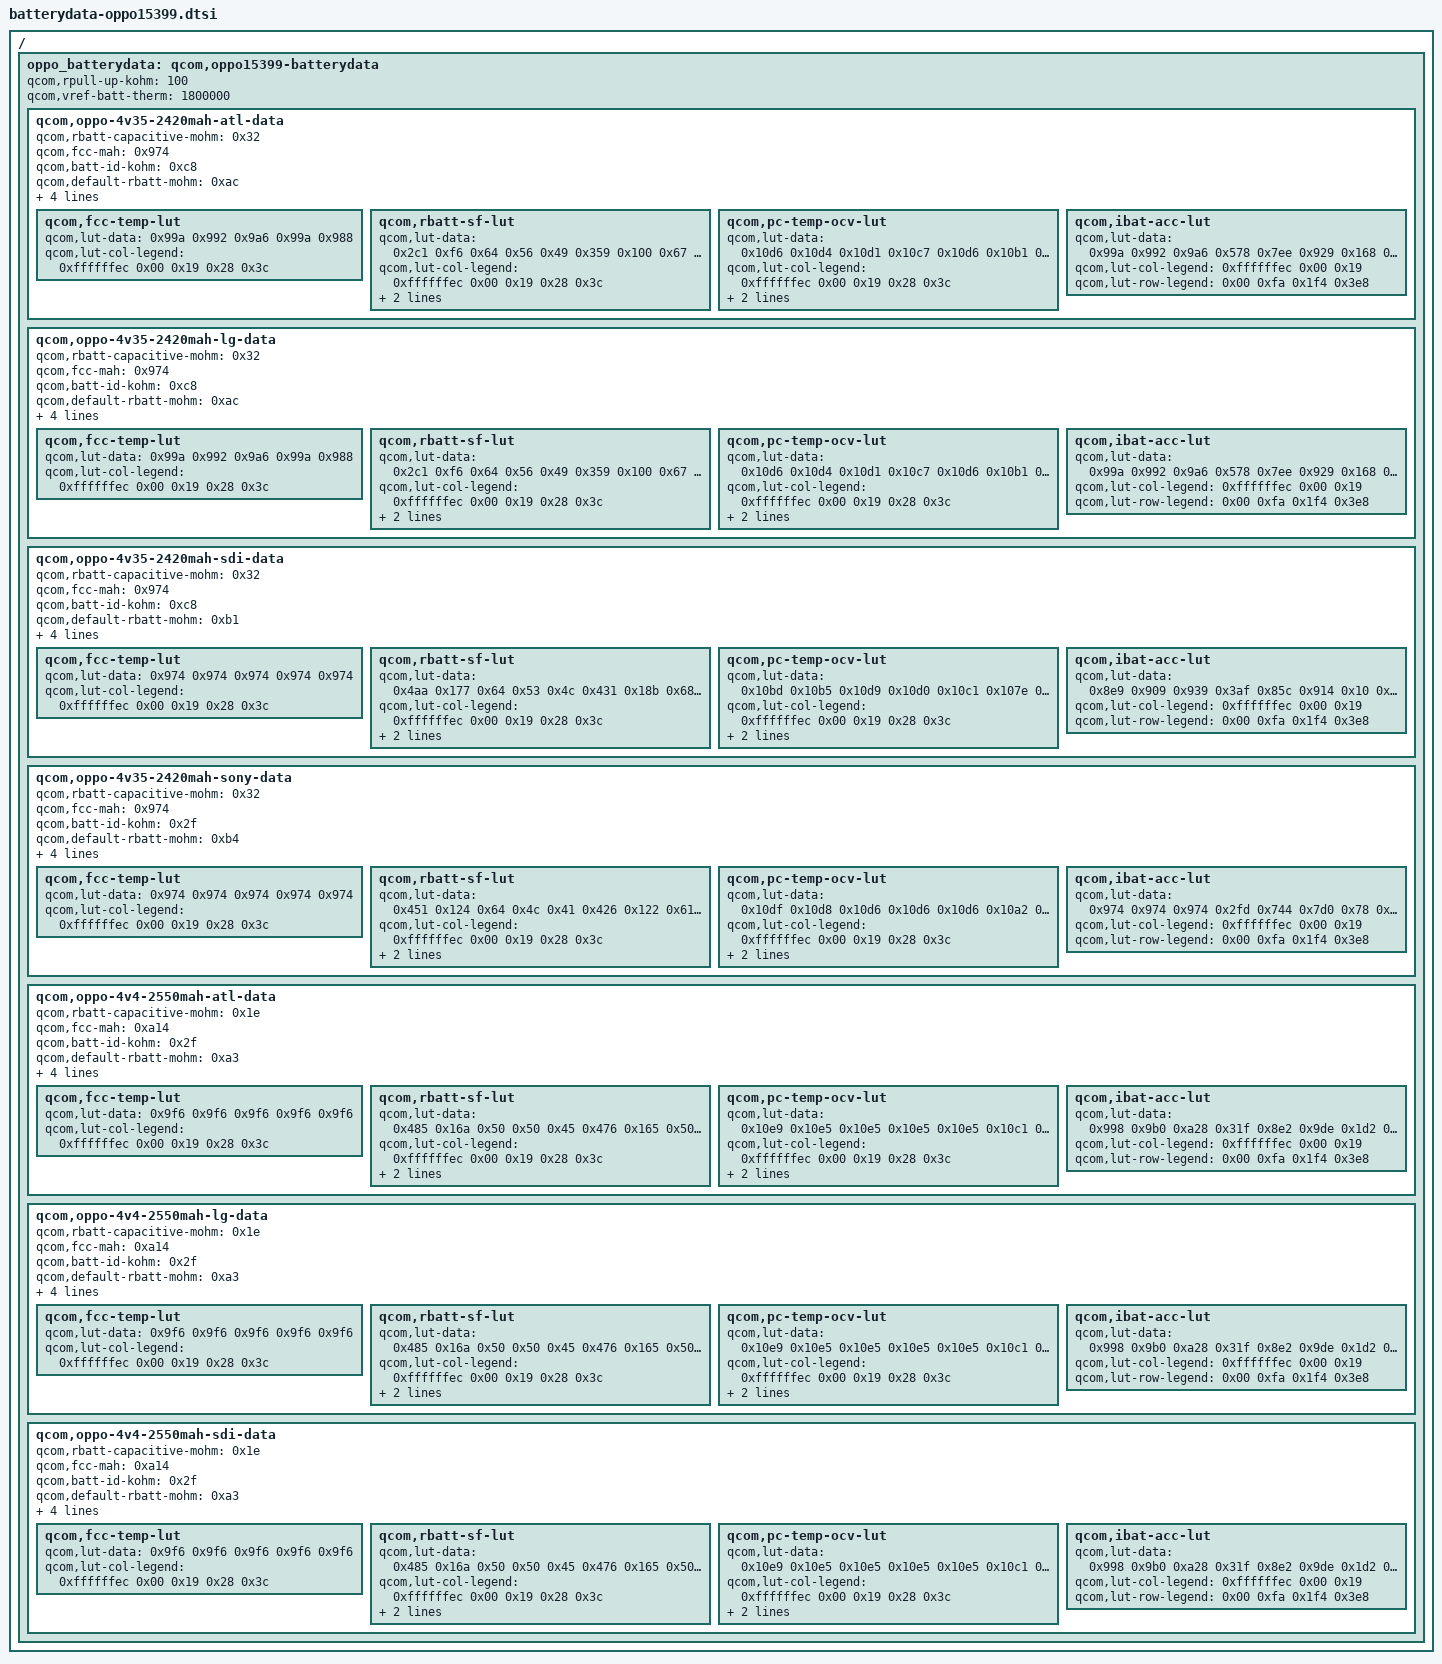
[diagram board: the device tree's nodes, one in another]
/* OPPO A37f (15399) fuel-gauge battery profiles — ported verbatim from the
 * live device-tree dump (~/a37f-dumps/live-refs/live-dt/qcom,battery-data-*).
 * Each live vendor container held one profile; here all 7 are collected into a
 * single qpnp-vm-bms container (referenced by &pm8916_bms). Profile node names
 * were made unique (per vendor); every value/LUT is unchanged ground truth.
 *
 * NOTE: live batt-id-kohm is shared (atl/lg/sdi=200; sony/high-*=47), so the
 * per-vendor and 4v35-vs-4v4 selection is an OPPO-custom mechanism the generic
 * vm-bms lacks — it first-matches by batt-id. Faithful data; selection caveat.
 */

/ {
	oppo_batterydata: qcom,oppo15399-batterydata {
		qcom,rpull-up-kohm = <100>;
		qcom,vref-batt-therm = <1800000>;

		qcom,oppo-4v35-2420mah-atl-data {
			qcom,rbatt-capacitive-mohm = <0x32>;
			qcom,fcc-mah = <0x974>;
			qcom,batt-id-kohm = <0xc8>;
			qcom,default-rbatt-mohm = <0xac>;
			qcom,flat-ocv-threshold-uv = <0x39fbc0>;
			qcom,v-cutoff-uv = <0x33e140>;
			qcom,battery-type = "oppo_4v35_2420mah_atl";
			qcom,max-voltage-uv = <0x426030>;
			qcom,fcc-temp-lut {
			qcom,lut-data = <0x99a 0x992 0x9a6 0x99a 0x988>;
			qcom,lut-col-legend = <0xffffffec 0x00 0x19 0x28 0x3c>;
			};
			qcom,rbatt-sf-lut {
			qcom,lut-data = <0x2c1 0xf6 0x64 0x56 0x49 0x359 0x100 0x67 0x56 0x4e 0x388 0x104 0x6b 0x58 0x4c 0x376 0x109 0x6c 0x5b 0x4e 0x33f 0x10d 0x70 0x5d 0x4f 0x350 0x115 0x75 0x5f 0x50 0x36d 0x111 0x76 0x63 0x54 0x30d 0x111 0x7c 0x69 0x56 0x32a 0x100 0x75 0x67 0x5a 0x339 0xfa 0x65 0x59 0x50 0x30c 0xf9 0x60 0x56 0x4e 0x317 0x100 0x63 0x58 0x4e 0x343 0x104 0x62 0x5a 0x4f 0x360 0x126 0x63 0x5b 0x52 0x371 0x103 0x64 0x58 0x4d 0x3c5 0x10b 0x62 0x54 0x4d 0x450 0x114 0x62 0x55 0x4d 0x43f 0x11c 0x61 0x56 0x4d 0x4a2 0x124 0x61 0x57 0x4d 0x4d1 0x12c 0x63 0x57 0x4f 0x518 0x13a 0x64 0x59 0x50 0x541 0x140 0x68 0x5d 0x52 0x569 0x153 0x6c 0x5e 0x52 0x598 0x172 0x6f 0x5d 0x52 0x60f 0x185 0x73 0x61 0x52 0x65c 0x19c 0x73 0x60 0x53 0xfd1 0x1c7 0x76 0x63 0x57 0x1d83 0x1ef 0x7d 0x65 0x5b 0x2f84 0x224 0x81 0x74 0x69 0x5ea2 0x27c 0x91 0x92 0x81 0x21053 0x1e80c 0x12c 0x125 0x12c>;
			qcom,lut-col-legend = <0xffffffec 0x00 0x19 0x28 0x3c>;
			qcom,lut-row-legend = <0x64 0x5f 0x5a 0x55 0x50 0x4b 0x46 0x41 0x3c 0x37 0x32 0x2d 0x28 0x23 0x1e 0x19 0x14 0x10 0x0d 0x0b 0x0a 0x09 0x08 0x07 0x06 0x05 0x04 0x03 0x02 0x01 0x00>;
			};
			qcom,pc-temp-ocv-lut {
			qcom,lut-data = <0x10d6 0x10d4 0x10d1 0x10c7 0x10d6 0x10b1 0x10bf 0x10ae 0x109e 0x10a6 0x1074 0x1085 0x107c 0x1067 0x106d 0x103a 0x104f 0x104a 0x1032 0x1036 0x1002 0x101b 0x1018 0xffe 0x1004 0xfc6 0xfe4 0xfe6 0xfc5 0xfca 0xf84 0xfac 0xfc3 0xf99 0xf9f 0xf59 0xf7b 0xfa3 0xf72 0xf76 0xf35 0xf4b 0xf7b 0xf48 0xf4e 0xf14 0xf22 0xf4d 0xf17 0xf1e 0xef9 0xf05 0xf1a 0xefa 0xf01 0xee0 0xef0 0xefe 0xee0 0xeea 0xecc 0xedf 0xee9 0xece 0xed7 0xebf 0xecf 0xed7 0xec0 0xec7 0xeb6 0xec3 0xec8 0xeb0 0xeb2 0xea9 0xeba 0xebb 0xe9e 0xe94 0xe98 0xeaa 0xead 0xe8b 0xe80 0xe85 0xe90 0xe97 0xe73 0xe67 0xe78 0xe78 0xe7e 0xe5c 0xe55 0xe6f 0xe73 0xe6c 0xe56 0xe51 0xe68 0xe71 0xe64 0xe55 0xe50 0xe5b 0xe6d 0xe62 0xe52 0xe4e 0xe52 0xe68 0xe5f 0xe4e 0xe4c 0xe37 0xe62 0xe56 0xe3f 0xe3e 0xe21 0xe59 0xe46 0xe24 0xe28 0xdfe 0xe1c 0xdfd 0xdfe 0xe06 0xdce 0xded 0xdc9 0xdce 0xddd 0xd91 0xdb0 0xd83 0xd91 0xda7 0xd40 0xd5e 0xd24 0xd40 0xd01 0xcc8 0xce1 0xc81 0xcc8 0xca8 0xbb8 0xbb8 0xbb8 0xbb8 0xbb8>;
			qcom,lut-col-legend = <0xffffffec 0x00 0x19 0x28 0x3c>;
			qcom,lut-row-legend = <0x64 0x5f 0x5a 0x55 0x50 0x4b 0x46 0x41 0x3c 0x37 0x32 0x2d 0x28 0x23 0x1e 0x19 0x14 0x10 0x0d 0x0b 0x0a 0x09 0x08 0x07 0x06 0x05 0x04 0x03 0x02 0x01 0x00>;
			};
			qcom,ibat-acc-lut {
			qcom,lut-data = <0x99a 0x992 0x9a6 0x578 0x7ee 0x929 0x168 0x690 0x906 0x00 0x3fc 0x898>;
			qcom,lut-col-legend = <0xffffffec 0x00 0x19>;
			qcom,lut-row-legend = <0x00 0xfa 0x1f4 0x3e8>;
			};
		};

		qcom,oppo-4v35-2420mah-lg-data {
			qcom,rbatt-capacitive-mohm = <0x32>;
			qcom,fcc-mah = <0x974>;
			qcom,batt-id-kohm = <0xc8>;
			qcom,default-rbatt-mohm = <0xac>;
			qcom,flat-ocv-threshold-uv = <0x39fbc0>;
			qcom,v-cutoff-uv = <0x33e140>;
			qcom,battery-type = "oppo_4v35_2420mah_lg";
			qcom,max-voltage-uv = <0x426030>;
			qcom,fcc-temp-lut {
			qcom,lut-data = <0x99a 0x992 0x9a6 0x99a 0x988>;
			qcom,lut-col-legend = <0xffffffec 0x00 0x19 0x28 0x3c>;
			};
			qcom,rbatt-sf-lut {
			qcom,lut-data = <0x2c1 0xf6 0x64 0x56 0x49 0x359 0x100 0x67 0x56 0x4e 0x388 0x104 0x6b 0x58 0x4c 0x376 0x109 0x6c 0x5b 0x4e 0x33f 0x10d 0x70 0x5d 0x4f 0x350 0x115 0x75 0x5f 0x50 0x36d 0x111 0x76 0x63 0x54 0x30d 0x111 0x7c 0x69 0x56 0x32a 0x100 0x75 0x67 0x5a 0x339 0xfa 0x65 0x59 0x50 0x30c 0xf9 0x60 0x56 0x4e 0x317 0x100 0x63 0x58 0x4e 0x343 0x104 0x62 0x5a 0x4f 0x360 0x126 0x63 0x5b 0x52 0x371 0x103 0x64 0x58 0x4d 0x3c5 0x10b 0x62 0x54 0x4d 0x450 0x114 0x62 0x55 0x4d 0x43f 0x11c 0x61 0x56 0x4d 0x4a2 0x124 0x61 0x57 0x4d 0x4d1 0x12c 0x63 0x57 0x4f 0x518 0x13a 0x64 0x59 0x50 0x541 0x140 0x68 0x5d 0x52 0x569 0x153 0x6c 0x5e 0x52 0x598 0x172 0x6f 0x5d 0x52 0x60f 0x185 0x73 0x61 0x52 0x65c 0x19c 0x73 0x60 0x53 0xfd1 0x1c7 0x76 0x63 0x57 0x1d83 0x1ef 0x7d 0x65 0x5b 0x2f84 0x224 0x81 0x74 0x69 0x5ea2 0x27c 0x91 0x92 0x81 0x21053 0x1e80c 0x12c 0x125 0x12c>;
			qcom,lut-col-legend = <0xffffffec 0x00 0x19 0x28 0x3c>;
			qcom,lut-row-legend = <0x64 0x5f 0x5a 0x55 0x50 0x4b 0x46 0x41 0x3c 0x37 0x32 0x2d 0x28 0x23 0x1e 0x19 0x14 0x10 0x0d 0x0b 0x0a 0x09 0x08 0x07 0x06 0x05 0x04 0x03 0x02 0x01 0x00>;
			};
			qcom,pc-temp-ocv-lut {
			qcom,lut-data = <0x10d6 0x10d4 0x10d1 0x10c7 0x10d6 0x10b1 0x10bf 0x10ae 0x109e 0x10a6 0x1074 0x1085 0x107c 0x1067 0x106d 0x103a 0x104f 0x104a 0x1032 0x1036 0x1002 0x101b 0x1018 0xffe 0x1004 0xfc6 0xfe4 0xfe6 0xfc5 0xfca 0xf84 0xfac 0xfc3 0xf99 0xf9f 0xf59 0xf7b 0xfa3 0xf72 0xf76 0xf35 0xf4b 0xf7b 0xf48 0xf4e 0xf14 0xf22 0xf4d 0xf17 0xf1e 0xef9 0xf05 0xf1a 0xefa 0xf01 0xee0 0xef0 0xefe 0xee0 0xeea 0xecc 0xedf 0xee9 0xece 0xed7 0xebf 0xecf 0xed7 0xec0 0xec7 0xeb6 0xec3 0xec8 0xeb0 0xeb2 0xea9 0xeba 0xebb 0xe9e 0xe94 0xe98 0xeaa 0xead 0xe8b 0xe80 0xe85 0xe90 0xe97 0xe73 0xe67 0xe78 0xe78 0xe7e 0xe5c 0xe55 0xe6f 0xe73 0xe6c 0xe56 0xe51 0xe68 0xe71 0xe64 0xe55 0xe50 0xe5b 0xe6d 0xe62 0xe52 0xe4e 0xe52 0xe68 0xe5f 0xe4e 0xe4c 0xe37 0xe62 0xe56 0xe3f 0xe3e 0xe21 0xe59 0xe46 0xe24 0xe28 0xdfe 0xe1c 0xdfd 0xdfe 0xe06 0xdce 0xded 0xdc9 0xdce 0xddd 0xd91 0xdb0 0xd83 0xd91 0xda7 0xd40 0xd5e 0xd24 0xd40 0xd01 0xcc8 0xce1 0xc81 0xcc8 0xca8 0xbb8 0xbb8 0xbb8 0xbb8 0xbb8>;
			qcom,lut-col-legend = <0xffffffec 0x00 0x19 0x28 0x3c>;
			qcom,lut-row-legend = <0x64 0x5f 0x5a 0x55 0x50 0x4b 0x46 0x41 0x3c 0x37 0x32 0x2d 0x28 0x23 0x1e 0x19 0x14 0x10 0x0d 0x0b 0x0a 0x09 0x08 0x07 0x06 0x05 0x04 0x03 0x02 0x01 0x00>;
			};
			qcom,ibat-acc-lut {
			qcom,lut-data = <0x99a 0x992 0x9a6 0x578 0x7ee 0x929 0x168 0x690 0x906 0x00 0x3fc 0x898>;
			qcom,lut-col-legend = <0xffffffec 0x00 0x19>;
			qcom,lut-row-legend = <0x00 0xfa 0x1f4 0x3e8>;
			};
		};

		qcom,oppo-4v35-2420mah-sdi-data {
			qcom,rbatt-capacitive-mohm = <0x32>;
			qcom,fcc-mah = <0x974>;
			qcom,batt-id-kohm = <0xc8>;
			qcom,default-rbatt-mohm = <0xb1>;
			qcom,flat-ocv-threshold-uv = <0x39fbc0>;
			qcom,v-cutoff-uv = <0x33e140>;
			qcom,battery-type = "oppo_4v35_2420mah_sdi";
			qcom,max-voltage-uv = <0x426030>;
			qcom,fcc-temp-lut {
			qcom,lut-data = <0x974 0x974 0x974 0x974 0x974>;
			qcom,lut-col-legend = <0xffffffec 0x00 0x19 0x28 0x3c>;
			};
			qcom,rbatt-sf-lut {
			qcom,lut-data = <0x4aa 0x177 0x64 0x53 0x4c 0x431 0x18b 0x68 0x56 0x4e 0x3df 0x172 0x6a 0x53 0x4c 0x3ac 0x172 0x6c 0x55 0x50 0x38d 0x15c 0x65 0x57 0x50 0x355 0x155 0x6e 0x5e 0x52 0x346 0x14d 0x6b 0x5c 0x59 0x346 0x139 0x73 0x63 0x5c 0x344 0x125 0x6a 0x52 0x4f 0x346 0x124 0x62 0x4e 0x4c 0x34f 0x139 0x63 0x55 0x50 0x363 0x124 0x60 0x53 0x50 0x373 0x123 0x60 0x59 0x52 0x38b 0x136 0x63 0x5a 0x53 0x3b0 0x14d 0x62 0x56 0x52 0x3de 0x155 0x63 0x53 0x4f 0x416 0x162 0x66 0x57 0x4f 0x439 0x180 0x69 0x53 0x50 0x46f 0x18f 0x6c 0x55 0x50 0x48b 0x1a1 0x65 0x57 0x53 0x4a2 0x1b2 0x63 0x56 0x50 0x4b4 0x1b7 0x64 0x59 0x50 0x4dd 0x1d4 0x65 0x59 0x56 0x4f4 0x1cc 0x69 0x5c 0x53 0x511 0x1ee 0x6b 0x59 0x52 0x526 0x1e2 0x6c 0x59 0x55 0x541 0x1f0 0x6f 0x59 0x57 0x55b 0x1f6 0x72 0x5c 0x5a 0x59b 0x218 0x77 0x74 0x6e 0x69d 0x261 0xb6 0x2c4 0x1d0 0x7b7 0x333 0x14b 0x338 0x226>;
			qcom,lut-col-legend = <0xffffffec 0x00 0x19 0x28 0x3c>;
			qcom,lut-row-legend = <0x64 0x5f 0x5a 0x55 0x50 0x4b 0x46 0x41 0x3c 0x37 0x32 0x2d 0x28 0x23 0x1e 0x19 0x14 0x10 0x0d 0x0b 0x0a 0x09 0x08 0x07 0x06 0x05 0x04 0x03 0x02 0x01 0x00>;
			};
			qcom,pc-temp-ocv-lut {
			qcom,lut-data = <0x10bd 0x10b5 0x10d9 0x10d0 0x10c1 0x107e 0x107d 0x109e 0x1097 0x1089 0x1049 0x1047 0x1068 0x105f 0x1051 0x101c 0x101e 0x1035 0x102d 0x101e 0xfec 0xff1 0x1000 0xff7 0xff4 0xfa6 0xfbb 0xfd9 0xfd5 0xfc5 0xf63 0xf7c 0xf98 0xfa0 0xf99 0xf45 0xf61 0xf80 0xf7d 0xf73 0xf2d 0xf36 0xf4d 0xf43 0xf3f 0xf13 0xf0f 0xf1c 0xf1e 0xf16 0xefa 0xef5 0xf01 0xf01 0xf01 0xee5 0xee2 0xeeb 0xef1 0xeeb 0xed4 0xed3 0xed9 0xee1 0xedc 0xecb 0xec7 0xecc 0xed0 0xecc 0xec1 0xeb9 0xebd 0xeba 0xeaf 0xeb5 0xeb1 0xeac 0xea6 0xe9a 0xea3 0xe9f 0xe9a 0xe98 0xe83 0xe93 0xe8b 0xe82 0xe7c 0xe6e 0xe87 0xe72 0xe6f 0xe6a 0xe5c 0xe82 0xe6e 0xe67 0xe69 0xe5c 0xe7f 0xe6c 0xe66 0xe67 0xe59 0xe7d 0xe6c 0xe65 0xe67 0xe58 0xe76 0xe6a 0xe64 0xe62 0xe54 0xe71 0xe68 0xe63 0xe5d 0xe4d 0xe69 0xe66 0xe56 0xe4a 0xe37 0xe5b 0xe57 0xe3b 0xe24 0xe15 0xe47 0xe39 0xe14 0xdf8 0xdea 0xe2c 0xe12 0xde1 0xdc0 0xdb2 0xdd2 0xd9e 0xda0 0xd06 0xd01 0xd34 0xd38 0xca1 0xc47 0xc4f 0xbb8 0xbb8 0xbb8 0xbb8 0xbb8>;
			qcom,lut-col-legend = <0xffffffec 0x00 0x19 0x28 0x3c>;
			qcom,lut-row-legend = <0x64 0x5f 0x5a 0x55 0x50 0x4b 0x46 0x41 0x3c 0x37 0x32 0x2d 0x28 0x23 0x1e 0x19 0x14 0x10 0x0d 0x0b 0x0a 0x09 0x08 0x07 0x06 0x05 0x04 0x03 0x02 0x01 0x00>;
			};
			qcom,ibat-acc-lut {
			qcom,lut-data = <0x8e9 0x909 0x939 0x3af 0x85c 0x914 0x10 0x577 0x8f4 0x00 0x566 0x8a9>;
			qcom,lut-col-legend = <0xffffffec 0x00 0x19>;
			qcom,lut-row-legend = <0x00 0xfa 0x1f4 0x3e8>;
			};
		};

		qcom,oppo-4v35-2420mah-sony-data {
			qcom,rbatt-capacitive-mohm = <0x32>;
			qcom,fcc-mah = <0x974>;
			qcom,batt-id-kohm = <0x2f>;
			qcom,default-rbatt-mohm = <0xb4>;
			qcom,flat-ocv-threshold-uv = <0x39fbc0>;
			qcom,v-cutoff-uv = <0x33e140>;
			qcom,battery-type = "oppo_4v35_2420mah_sony";
			qcom,max-voltage-uv = <0x426030>;
			qcom,fcc-temp-lut {
			qcom,lut-data = <0x974 0x974 0x974 0x974 0x974>;
			qcom,lut-col-legend = <0xffffffec 0x00 0x19 0x28 0x3c>;
			};
			qcom,rbatt-sf-lut {
			qcom,lut-data = <0x451 0x124 0x64 0x4c 0x41 0x426 0x122 0x61 0x4c 0x42 0x3f2 0x119 0x61 0x4c 0x41 0x3cd 0x117 0x64 0x4c 0x43 0x3bc 0x114 0x66 0x51 0x45 0x3b8 0x11d 0x67 0x4f 0x43 0x3b0 0x116 0x6c 0x53 0x46 0x3ac 0x119 0x70 0x56 0x48 0x3a9 0x119 0x72 0x55 0x4b 0x3aa 0x10f 0x6b 0x51 0x46 0x3b3 0x108 0x66 0x4c 0x42 0x3be 0x112 0x67 0x4c 0x44 0x3ca 0x119 0x67 0x4f 0x48 0x3e9 0x11a 0x66 0x53 0x49 0x40c 0x12c 0x6b 0x51 0x45 0x43d 0x13a 0x6a 0x4e 0x44 0x47d 0x146 0x6a 0x4e 0x44 0x4c6 0x156 0x6b 0x4c 0x44 0x50a 0x16c 0x6d 0x4e 0x44 0x567 0x181 0x6f 0x52 0x46 0x58d 0x191 0x73 0x55 0x47 0x5bd 0x1a3 0x7a 0x53 0x49 0x5f2 0x1b6 0x7f 0x58 0x4a 0x630 0x1c8 0x83 0x58 0x4c 0x640 0x1e3 0x84 0x56 0x4b 0x6a4 0x203 0x87 0x56 0x4b 0x708 0x235 0x8e 0x58 0x4e 0x76c 0x274 0x99 0x63 0x53 0x7d0 0x2e2 0xab 0x65 0x5a 0x1388 0x3e8 0xe8 0x7e 0x6a 0x21053 0x1e80c 0xe6cf 0x144 0xd0>;
			qcom,lut-col-legend = <0xffffffec 0x00 0x19 0x28 0x3c>;
			qcom,lut-row-legend = <0x64 0x5f 0x5a 0x55 0x50 0x4b 0x46 0x41 0x3c 0x37 0x32 0x2d 0x28 0x23 0x1e 0x19 0x14 0x10 0x0d 0x0b 0x0a 0x09 0x08 0x07 0x06 0x05 0x04 0x03 0x02 0x01 0x00>;
			};
			qcom,pc-temp-ocv-lut {
			qcom,lut-data = <0x10df 0x10d8 0x10d6 0x10d6 0x10d6 0x10a2 0x109c 0x10a1 0x10a4 0x109a 0x1065 0x106a 0x106d 0x1072 0x105d 0x102f 0x103f 0x1042 0x1045 0x1032 0xffd 0x100b 0x100f 0x1013 0x1000 0xfcc 0xfd6 0xfe0 0xfd8 0xfd0 0xf94 0xfa2 0xfab 0xfac 0xf9b 0xf6d 0xf7e 0xf85 0xf86 0xf75 0xf3e 0xf57 0xf5f 0xf5f 0xf4f 0xf1a 0xf28 0xf33 0xf34 0xf22 0xefe 0xf05 0xf0d 0xf0d 0xf00 0xee9 0xef0 0xef0 0xef4 0xee9 0xed9 0xede 0xede 0xee2 0xed7 0xece 0xed0 0xecf 0xed3 0xec7 0xec5 0xec9 0xec3 0xec5 0xeb1 0xeba 0xebe 0xeaf 0xeaf 0xe8f 0xea5 0xea2 0xe9a 0xe95 0xe7a 0xe8d 0xe82 0xe7e 0xe78 0xe5f 0xe7a 0xe74 0xe68 0xe64 0xe4d 0xe6d 0xe6d 0xe64 0xe63 0xe4a 0xe68 0xe6c 0xe63 0xe61 0xe47 0xe60 0xe69 0xe5e 0xe5b 0xe45 0xe56 0xe61 0xe59 0xe57 0xe40 0xe46 0xe54 0xe4e 0xe4d 0xe36 0xe36 0xe36 0xe33 0xe37 0xe1d 0xe0e 0xe07 0xe07 0xe0e 0xdf7 0xddb 0xdca 0xdd0 0xddd 0xdc8 0xd98 0xd77 0xd87 0xd9d 0xd8b 0xd41 0xcfe 0xd24 0xd44 0xd3e 0xcc0 0xc86 0xc86 0xcc6 0xcce 0xbb8 0xbb8 0xbb8 0xbb8 0xbb8>;
			qcom,lut-col-legend = <0xffffffec 0x00 0x19 0x28 0x3c>;
			qcom,lut-row-legend = <0x64 0x5f 0x5a 0x55 0x50 0x4b 0x46 0x41 0x3c 0x37 0x32 0x2d 0x28 0x23 0x1e 0x19 0x14 0x10 0x0d 0x0b 0x0a 0x09 0x08 0x07 0x06 0x05 0x04 0x03 0x02 0x01 0x00>;
			};
			qcom,ibat-acc-lut {
			qcom,lut-data = <0x974 0x974 0x974 0x2fd 0x744 0x7d0 0x78 0x668 0x7c6 0x00 0x4ce 0x778>;
			qcom,lut-col-legend = <0xffffffec 0x00 0x19>;
			qcom,lut-row-legend = <0x00 0xfa 0x1f4 0x3e8>;
			};
		};

		qcom,oppo-4v4-2550mah-atl-data {
			qcom,rbatt-capacitive-mohm = <0x1e>;
			qcom,fcc-mah = <0xa14>;
			qcom,batt-id-kohm = <0x2f>;
			qcom,default-rbatt-mohm = <0xa3>;
			qcom,flat-ocv-threshold-uv = <0x3abf10>;
			qcom,v-cutoff-uv = <0x33e140>;
			qcom,battery-type = "oppo_4400_2550mah_ATL";
			qcom,max-voltage-uv = <0x432380>;
			qcom,fcc-temp-lut {
			qcom,lut-data = <0x9f6 0x9f6 0x9f6 0x9f6 0x9f6>;
			qcom,lut-col-legend = <0xffffffec 0x00 0x19 0x28 0x3c>;
			};
			qcom,rbatt-sf-lut {
			qcom,lut-data = <0x485 0x16a 0x50 0x50 0x45 0x476 0x165 0x50 0x53 0x49 0x452 0x15e 0x66 0x54 0x4c 0x42e 0x156 0x69 0x5a 0x4b 0x408 0x153 0x6a 0x59 0x4e 0x3f3 0x159 0x6f 0x59 0x50 0x3c9 0x144 0x71 0x5f 0x4e 0x3bc 0x144 0x77 0x63 0x50 0x3b6 0x127 0x70 0x5f 0x53 0x3af 0x12b 0x61 0x56 0x4c 0x3b7 0x12a 0x5f 0x50 0x49 0x3c3 0x130 0x61 0x51 0x49 0x3c6 0x131 0x64 0x53 0x4b 0x3da 0x137 0x67 0x57 0x51 0x402 0x139 0x61 0x53 0x49 0x42b 0x13b 0x60 0x4e 0x49 0x467 0x13e 0x64 0x53 0x4b 0x4b5 0x140 0x64 0x56 0x4b 0x4f8 0x169 0x62 0x54 0x49 0x520 0x174 0x63 0x53 0x4e 0x532 0x17d 0x65 0x57 0x4c 0x560 0x17f 0x68 0x56 0x4b 0x579 0x185 0x6c 0x57 0x4e 0x594 0x189 0x71 0x5c 0x4c 0x5b0 0x197 0x6e 0x59 0x4e 0x5f9 0x1a5 0x6d 0x59 0x4b 0x61e 0x1af 0x72 0x5a 0x4e 0x64d 0x1c0 0x7a 0x60 0x53 0x687 0x1f3 0x81 0x68 0x5a 0x673 0x227 0x326 0xaa 0x6b 0x11eb 0x325 0x395 0xe5 0x2f2>;
			qcom,lut-col-legend = <0xffffffec 0x00 0x19 0x28 0x3c>;
			qcom,lut-row-legend = <0x64 0x5f 0x5a 0x55 0x50 0x4b 0x46 0x41 0x3c 0x37 0x32 0x2d 0x28 0x23 0x1e 0x19 0x14 0x10 0x0d 0x0b 0x0a 0x09 0x08 0x07 0x06 0x05 0x04 0x03 0x02 0x01 0x00>;
			};
			qcom,pc-temp-ocv-lut {
			qcom,lut-data = <0x10e9 0x10e5 0x10e5 0x10e5 0x10e5 0x10c1 0x10c5 0x10c5 0x10c5 0x10c5 0x1087 0x107f 0x109b 0x109c 0x1092 0x1052 0x104b 0x1065 0x1068 0x105e 0x1015 0x1017 0x102a 0x102b 0x1029 0xfe7 0xfe4 0xff0 0xff9 0xfee 0xf9e 0xfa6 0xfc1 0xfc2 0xfbf 0xf6d 0xf7b 0xf8e 0xf93 0xf8f 0xf46 0xf4e 0xf65 0xf6c 0xf64 0xf22 0xf22 0xf2c 0xf30 0xf31 0xf06 0xf07 0xf10 0xf14 0xf0f 0xef0 0xeed 0xef5 0xef9 0xef8 0xedd 0xede 0xee5 0xee5 0xee1 0xed0 0xece 0xed4 0xed5 0xed3 0xec7 0xebe 0xec3 0xec5 0xec2 0xebd 0xeaf 0xeb2 0xeaa 0xea0 0xeaf 0xe9d 0xe9f 0xe9b 0xe8d 0xe9f 0xe89 0xe8a 0xe87 0xe79 0xe8f 0xe76 0xe76 0xe73 0xe67 0xe86 0xe74 0xe71 0xe69 0xe5e 0xe81 0xe72 0xe6e 0xe69 0xe5f 0xe7b 0xe71 0xe6d 0xe69 0xe5d 0xe77 0xe70 0xe6e 0xe67 0xe5b 0xe74 0xe6b 0xe69 0xe64 0xe58 0xe71 0xe69 0xe65 0xe61 0xe54 0xe68 0xe5e 0xe56 0xe56 0xe34 0xe62 0xe48 0xe15 0xe1c 0xe14 0xe59 0xe25 0xde8 0xdf4 0xdee 0xe4d 0xdc4 0xdb2 0xdc4 0xdc0 0xe1b 0xd7d 0xcfe 0xd2c 0xd36 0xbb8 0xbb8 0xbb8 0xbb8 0xbb8>;
			qcom,lut-col-legend = <0xffffffec 0x00 0x19 0x28 0x3c>;
			qcom,lut-row-legend = <0x64 0x5f 0x5a 0x55 0x50 0x4b 0x46 0x41 0x3c 0x37 0x32 0x2d 0x28 0x23 0x1e 0x19 0x14 0x10 0x0d 0x0b 0x0a 0x09 0x08 0x07 0x06 0x05 0x04 0x03 0x02 0x01 0x00>;
			};
			qcom,ibat-acc-lut {
			qcom,lut-data = <0x998 0x9b0 0xa28 0x31f 0x8e2 0x9de 0x1d2 0x8da 0x9ca 0x00 0x555 0x970>;
			qcom,lut-col-legend = <0xffffffec 0x00 0x19>;
			qcom,lut-row-legend = <0x00 0xfa 0x1f4 0x3e8>;
			};
		};

		qcom,oppo-4v4-2550mah-lg-data {
			qcom,rbatt-capacitive-mohm = <0x1e>;
			qcom,fcc-mah = <0xa14>;
			qcom,batt-id-kohm = <0x2f>;
			qcom,default-rbatt-mohm = <0xa3>;
			qcom,flat-ocv-threshold-uv = <0x3abf10>;
			qcom,v-cutoff-uv = <0x33e140>;
			qcom,battery-type = "oppo_4400_2550mah_lg";
			qcom,max-voltage-uv = <0x432380>;
			qcom,fcc-temp-lut {
			qcom,lut-data = <0x9f6 0x9f6 0x9f6 0x9f6 0x9f6>;
			qcom,lut-col-legend = <0xffffffec 0x00 0x19 0x28 0x3c>;
			};
			qcom,rbatt-sf-lut {
			qcom,lut-data = <0x485 0x16a 0x50 0x50 0x45 0x476 0x165 0x50 0x53 0x49 0x452 0x15e 0x66 0x54 0x4c 0x42e 0x156 0x69 0x5a 0x4b 0x408 0x153 0x6a 0x59 0x4e 0x3f3 0x159 0x6f 0x59 0x50 0x3c9 0x144 0x71 0x5f 0x4e 0x3bc 0x144 0x77 0x63 0x50 0x3b6 0x127 0x70 0x5f 0x53 0x3af 0x12b 0x61 0x56 0x4c 0x3b7 0x12a 0x5f 0x50 0x49 0x3c3 0x130 0x61 0x51 0x49 0x3c6 0x131 0x64 0x53 0x4b 0x3da 0x137 0x67 0x57 0x51 0x402 0x139 0x61 0x53 0x49 0x42b 0x13b 0x60 0x4e 0x49 0x467 0x13e 0x64 0x53 0x4b 0x4b5 0x140 0x64 0x56 0x4b 0x4f8 0x169 0x62 0x54 0x49 0x520 0x174 0x63 0x53 0x4e 0x532 0x17d 0x65 0x57 0x4c 0x560 0x17f 0x68 0x56 0x4b 0x579 0x185 0x6c 0x57 0x4e 0x594 0x189 0x71 0x5c 0x4c 0x5b0 0x197 0x6e 0x59 0x4e 0x5f9 0x1a5 0x6d 0x59 0x4b 0x61e 0x1af 0x72 0x5a 0x4e 0x64d 0x1c0 0x7a 0x60 0x53 0x687 0x1f3 0x81 0x68 0x5a 0x673 0x227 0x326 0xaa 0x6b 0x11eb 0x325 0x395 0xe5 0x2f2>;
			qcom,lut-col-legend = <0xffffffec 0x00 0x19 0x28 0x3c>;
			qcom,lut-row-legend = <0x64 0x5f 0x5a 0x55 0x50 0x4b 0x46 0x41 0x3c 0x37 0x32 0x2d 0x28 0x23 0x1e 0x19 0x14 0x10 0x0d 0x0b 0x0a 0x09 0x08 0x07 0x06 0x05 0x04 0x03 0x02 0x01 0x00>;
			};
			qcom,pc-temp-ocv-lut {
			qcom,lut-data = <0x10e9 0x10e5 0x10e5 0x10e5 0x10e5 0x10c1 0x10c5 0x10c5 0x10c5 0x10c5 0x1087 0x107f 0x109b 0x109c 0x1092 0x1052 0x104b 0x1065 0x1068 0x105e 0x1015 0x1017 0x102a 0x102b 0x1029 0xfe7 0xfe4 0xff0 0xff9 0xfee 0xf9e 0xfa6 0xfc1 0xfc2 0xfbf 0xf6d 0xf7b 0xf8e 0xf93 0xf8f 0xf46 0xf4e 0xf65 0xf6c 0xf64 0xf22 0xf22 0xf2c 0xf30 0xf31 0xf06 0xf07 0xf10 0xf14 0xf0f 0xef0 0xeed 0xef5 0xef9 0xef8 0xedd 0xede 0xee5 0xee5 0xee1 0xed0 0xece 0xed4 0xed5 0xed3 0xec7 0xebe 0xec3 0xec5 0xec2 0xebd 0xeaf 0xeb2 0xeaa 0xea0 0xeaf 0xe9d 0xe9f 0xe9b 0xe8d 0xe9f 0xe89 0xe8a 0xe87 0xe79 0xe8f 0xe76 0xe76 0xe73 0xe67 0xe86 0xe74 0xe71 0xe69 0xe5e 0xe81 0xe72 0xe6e 0xe69 0xe5f 0xe7b 0xe71 0xe6d 0xe69 0xe5d 0xe77 0xe70 0xe6e 0xe67 0xe5b 0xe74 0xe6b 0xe69 0xe64 0xe58 0xe71 0xe69 0xe65 0xe61 0xe54 0xe68 0xe5e 0xe56 0xe56 0xe34 0xe62 0xe48 0xe15 0xe1c 0xe14 0xe59 0xe25 0xde8 0xdf4 0xdee 0xe4d 0xdc4 0xdb2 0xdc4 0xdc0 0xe1b 0xd7d 0xcfe 0xd2c 0xd36 0xbb8 0xbb8 0xbb8 0xbb8 0xbb8>;
			qcom,lut-col-legend = <0xffffffec 0x00 0x19 0x28 0x3c>;
			qcom,lut-row-legend = <0x64 0x5f 0x5a 0x55 0x50 0x4b 0x46 0x41 0x3c 0x37 0x32 0x2d 0x28 0x23 0x1e 0x19 0x14 0x10 0x0d 0x0b 0x0a 0x09 0x08 0x07 0x06 0x05 0x04 0x03 0x02 0x01 0x00>;
			};
			qcom,ibat-acc-lut {
			qcom,lut-data = <0x998 0x9b0 0xa28 0x31f 0x8e2 0x9de 0x1d2 0x8da 0x9ca 0x00 0x555 0x970>;
			qcom,lut-col-legend = <0xffffffec 0x00 0x19>;
			qcom,lut-row-legend = <0x00 0xfa 0x1f4 0x3e8>;
			};
		};

		qcom,oppo-4v4-2550mah-sdi-data {
			qcom,rbatt-capacitive-mohm = <0x1e>;
			qcom,fcc-mah = <0xa14>;
			qcom,batt-id-kohm = <0x2f>;
			qcom,default-rbatt-mohm = <0xa3>;
			qcom,flat-ocv-threshold-uv = <0x3abf10>;
			qcom,v-cutoff-uv = <0x33e140>;
			qcom,battery-type = "oppo_4400_2550mah_sdi";
			qcom,max-voltage-uv = <0x432380>;
			qcom,fcc-temp-lut {
			qcom,lut-data = <0x9f6 0x9f6 0x9f6 0x9f6 0x9f6>;
			qcom,lut-col-legend = <0xffffffec 0x00 0x19 0x28 0x3c>;
			};
			qcom,rbatt-sf-lut {
			qcom,lut-data = <0x485 0x16a 0x50 0x50 0x45 0x476 0x165 0x50 0x53 0x49 0x452 0x15e 0x66 0x54 0x4c 0x42e 0x156 0x69 0x5a 0x4b 0x408 0x153 0x6a 0x59 0x4e 0x3f3 0x159 0x6f 0x59 0x50 0x3c9 0x144 0x71 0x5f 0x4e 0x3bc 0x144 0x77 0x63 0x50 0x3b6 0x127 0x70 0x5f 0x53 0x3af 0x12b 0x61 0x56 0x4c 0x3b7 0x12a 0x5f 0x50 0x49 0x3c3 0x130 0x61 0x51 0x49 0x3c6 0x131 0x64 0x53 0x4b 0x3da 0x137 0x67 0x57 0x51 0x402 0x139 0x61 0x53 0x49 0x42b 0x13b 0x60 0x4e 0x49 0x467 0x13e 0x64 0x53 0x4b 0x4b5 0x140 0x64 0x56 0x4b 0x4f8 0x169 0x62 0x54 0x49 0x520 0x174 0x63 0x53 0x4e 0x532 0x17d 0x65 0x57 0x4c 0x560 0x17f 0x68 0x56 0x4b 0x579 0x185 0x6c 0x57 0x4e 0x594 0x189 0x71 0x5c 0x4c 0x5b0 0x197 0x6e 0x59 0x4e 0x5f9 0x1a5 0x6d 0x59 0x4b 0x61e 0x1af 0x72 0x5a 0x4e 0x64d 0x1c0 0x7a 0x60 0x53 0x687 0x1f3 0x81 0x68 0x5a 0x673 0x227 0x326 0xaa 0x6b 0x11eb 0x325 0x395 0xe5 0x2f2>;
			qcom,lut-col-legend = <0xffffffec 0x00 0x19 0x28 0x3c>;
			qcom,lut-row-legend = <0x64 0x5f 0x5a 0x55 0x50 0x4b 0x46 0x41 0x3c 0x37 0x32 0x2d 0x28 0x23 0x1e 0x19 0x14 0x10 0x0d 0x0b 0x0a 0x09 0x08 0x07 0x06 0x05 0x04 0x03 0x02 0x01 0x00>;
			};
			qcom,pc-temp-ocv-lut {
			qcom,lut-data = <0x10e9 0x10e5 0x10e5 0x10e5 0x10e5 0x10c1 0x10c5 0x10c5 0x10c5 0x10c5 0x1087 0x107f 0x109b 0x109c 0x1092 0x1052 0x104b 0x1065 0x1068 0x105e 0x1015 0x1017 0x102a 0x102b 0x1029 0xfe7 0xfe4 0xff0 0xff9 0xfee 0xf9e 0xfa6 0xfc1 0xfc2 0xfbf 0xf6d 0xf7b 0xf8e 0xf93 0xf8f 0xf46 0xf4e 0xf65 0xf6c 0xf64 0xf22 0xf22 0xf2c 0xf30 0xf31 0xf06 0xf07 0xf10 0xf14 0xf0f 0xef0 0xeed 0xef5 0xef9 0xef8 0xedd 0xede 0xee5 0xee5 0xee1 0xed0 0xece 0xed4 0xed5 0xed3 0xec7 0xebe 0xec3 0xec5 0xec2 0xebd 0xeaf 0xeb2 0xeaa 0xea0 0xeaf 0xe9d 0xe9f 0xe9b 0xe8d 0xe9f 0xe89 0xe8a 0xe87 0xe79 0xe8f 0xe76 0xe76 0xe73 0xe67 0xe86 0xe74 0xe71 0xe69 0xe5e 0xe81 0xe72 0xe6e 0xe69 0xe5f 0xe7b 0xe71 0xe6d 0xe69 0xe5d 0xe77 0xe70 0xe6e 0xe67 0xe5b 0xe74 0xe6b 0xe69 0xe64 0xe58 0xe71 0xe69 0xe65 0xe61 0xe54 0xe68 0xe5e 0xe56 0xe56 0xe34 0xe62 0xe48 0xe15 0xe1c 0xe14 0xe59 0xe25 0xde8 0xdf4 0xdee 0xe4d 0xdc4 0xdb2 0xdc4 0xdc0 0xe1b 0xd7d 0xcfe 0xd2c 0xd36 0xbb8 0xbb8 0xbb8 0xbb8 0xbb8>;
			qcom,lut-col-legend = <0xffffffec 0x00 0x19 0x28 0x3c>;
			qcom,lut-row-legend = <0x64 0x5f 0x5a 0x55 0x50 0x4b 0x46 0x41 0x3c 0x37 0x32 0x2d 0x28 0x23 0x1e 0x19 0x14 0x10 0x0d 0x0b 0x0a 0x09 0x08 0x07 0x06 0x05 0x04 0x03 0x02 0x01 0x00>;
			};
			qcom,ibat-acc-lut {
			qcom,lut-data = <0x998 0x9b0 0xa28 0x31f 0x8e2 0x9de 0x1d2 0x8da 0x9ca 0x00 0x555 0x970>;
			qcom,lut-col-legend = <0xffffffec 0x00 0x19>;
			qcom,lut-row-legend = <0x00 0xfa 0x1f4 0x3e8>;
			};
		};

	};
};
